# PIC32CX5112MTSH128S1 register map
Vendor: Microchip Technology; Series: PIC32CXMTSH; File version: 0
CPU: CM4 r0p1, selectable endian, MPU, FPU, 4 interrupt priority bits, 96 interrupts
Registers are 32-bit, read-write, reset 0x0 unless marked. A register's access mark holds for its fields unless they carry their own. Offsets are from the block's base; [hi:lo] are bit positions; {n}, {i} and the like mark numbered series.

## FLEXCOM0 (part 2 of 2) — Flexible Serial Communication
Base 0x40000000; register names take the prefix FLEXCOM_
Same registers: FLEXCOM1 0x40004000, FLEXCOM2 0x40008000, FLEXCOM3 0x4000C000, FLEXCOM4 0x40010000, FLEXCOM5 0x40014000, FLEXCOM6 0x40018000, FLEXCOM7 0x4001C000
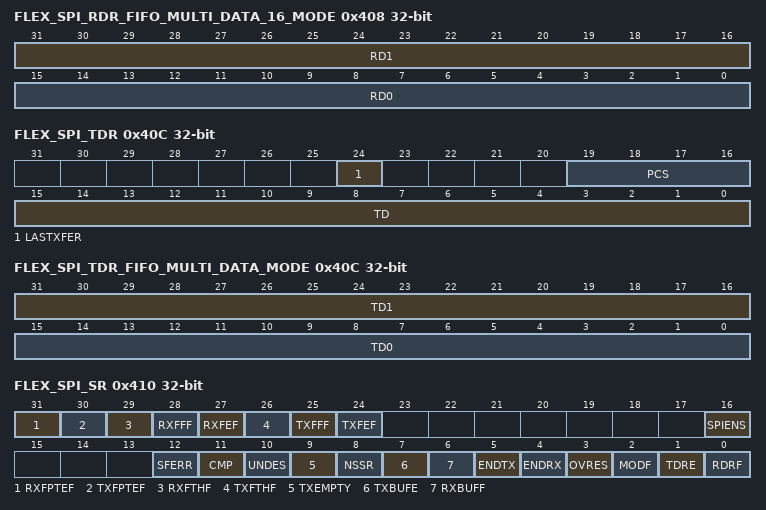
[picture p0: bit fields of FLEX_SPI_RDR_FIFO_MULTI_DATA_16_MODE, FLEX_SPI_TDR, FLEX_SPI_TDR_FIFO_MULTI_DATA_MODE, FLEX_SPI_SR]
0x408 FLEX_SPI_RDR_FIFO_MULTI_DATA_16_MODE ro (alternate view of FLEX_SPI_RDR) — SPI Receive Data Register
  [31:16] RD1 — Receive Data
  [15:0] RD0 — Receive Data
0x40C FLEX_SPI_TDR wo — SPI Transmit Data Register
  [24] LASTXFER — Last Transfer
  [19:16] PCS — Peripheral Chip Select
  [15:0] TD — Transmit Data
0x40C FLEX_SPI_TDR_FIFO_MULTI_DATA_MODE wo (alternate view of FLEX_SPI_TDR) — SPI Transmit Data Register
  [31:16] TD1 — Transmit Data
  [15:0] TD0 — Transmit Data
0x410 FLEX_SPI_SR ro — SPI Status Register
  [31] RXFPTEF — Receive FIFO Pointer Error Flag
  [30] TXFPTEF — Transmit FIFO Pointer Error Flag
  [29] RXFTHF — Receive FIFO Threshold Flag
  [28] RXFFF — Receive FIFO Full Flag
  [27] RXFEF — Receive FIFO Empty Flag
  [26] TXFTHF — Transmit FIFO Threshold Flag (cleared on read)
  [25] TXFFF — Transmit FIFO Full Flag (cleared on read)
  [24] TXFEF — Transmit FIFO Empty Flag (cleared on read)
  [16] SPIENS — SPI Enable Status
  [12] SFERR — Client Mode Frame Error (cleared on read)
  [11] CMP — Comparison Status (cleared on read)
  [10] UNDES — Underrun Error Status (Client mode only) (cleared on read)
  [9] TXEMPTY — Transmission Registers Empty (cleared by writing FLEX_SPI_TDR)
  [8] NSSR — NSS Rising (cleared on read)
  [7] TXBUFE — TX Buffer Empty (cleared by writing FLEX_SPI_TCR or FLEX_SPI_TNCR)
  [6] RXBUFF — RX Buffer Full (cleared by writing FLEX_SPI_RCR or FLEX_SPI_RNCR)
  [5] ENDTX — End of TX Buffer (cleared by writing FLEX_SPI_TCR or FLEX_SPI_TNCR)
  [4] ENDRX — End of RX Buffer (cleared by writing FLEX_SPI_RCR or FLEX_SPI_RNCR)
  [3] OVRES — Overrun Error Status (cleared on read)
  [2] MODF — Mode Fault Error (cleared on read)
  [1] TDRE — Transmit Data Register Empty (cleared by writing FLEX_SPI_TDR)
  [0] RDRF — Receive Data Register Full (cleared by reading FLEX_SPI_RDR)
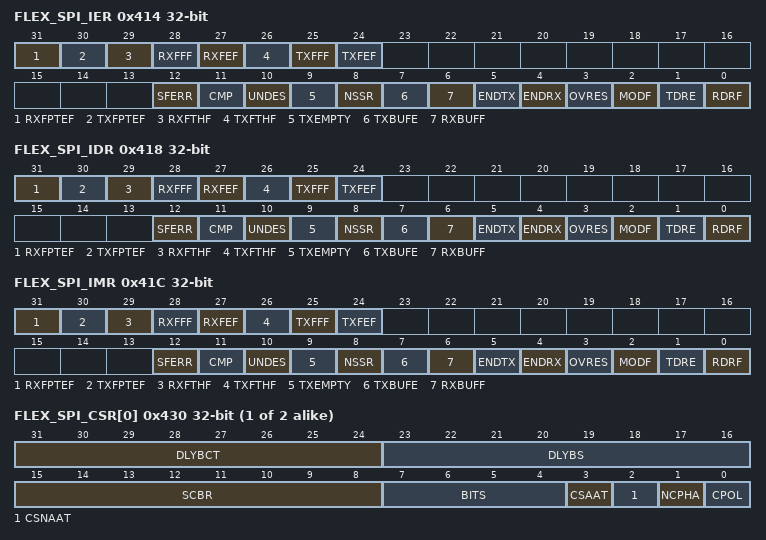
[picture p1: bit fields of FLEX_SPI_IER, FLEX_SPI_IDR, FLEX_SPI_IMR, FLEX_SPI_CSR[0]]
0x414 FLEX_SPI_IER wo — SPI Interrupt Enable Register
  [31] RXFPTEF — RXFPTEF Interrupt Enable
  [30] TXFPTEF — TXFPTEF Interrupt Enable
  [29] RXFTHF — RXFTHF Interrupt Enable
  [28] RXFFF — RXFFF Interrupt Enable
  [27] RXFEF — RXFEF Interrupt Enable
  [26] TXFTHF — TXFTHF Interrupt Enable
  [25] TXFFF — TXFFF Interrupt Enable
  [24] TXFEF — TXFEF Interrupt Enable
  [12] SFERR — Client Mode Frame Error Interrupt Enable
  [11] CMP — Comparison Interrupt Enable
  [10] UNDES — Underrun Error Interrupt Enable
  [9] TXEMPTY — Transmission Registers Empty Enable
  [8] NSSR — NSS Rising Interrupt Enable
  [7] TXBUFE — Transmit Buffer Empty Interrupt Enable
  [6] RXBUFF — Receive Buffer Full Interrupt Enable
  [5] ENDTX — End of Transmit Buffer Interrupt Enable
  [4] ENDRX — End of Receive Buffer Interrupt Enable
  [3] OVRES — Overrun Error Interrupt Enable
  [2] MODF — Mode Fault Error Interrupt Enable
  [1] TDRE — SPI Transmit Data Register Empty Interrupt Enable
  [0] RDRF — Receive Data Register Full Interrupt Enable
0x418 FLEX_SPI_IDR wo — SPI Interrupt Disable Register
  [31] RXFPTEF — RXFPTEF Interrupt Disable
  [30] TXFPTEF — TXFPTEF Interrupt Disable
  [29] RXFTHF — RXFTHF Interrupt Disable
  [28] RXFFF — RXFFF Interrupt Disable
  [27] RXFEF — RXFEF Interrupt Disable
  [26] TXFTHF — TXFTHF Interrupt Disable
  [25] TXFFF — TXFFF Interrupt Disable
  [24] TXFEF — TXFEF Interrupt Disable
  [12] SFERR — Client Mode Frame Error Interrupt Disable
  [11] CMP — Comparison Interrupt Disable
  [10] UNDES — Underrun Error Interrupt Disable
  [9] TXEMPTY — Transmission Registers Empty Disable
  [8] NSSR — NSS Rising Interrupt Disable
  [7] TXBUFE — Transmit Buffer Empty Interrupt Disable
  [6] RXBUFF — Receive Buffer Full Interrupt Disable
  [5] ENDTX — End of Transmit Buffer Interrupt Disable
  [4] ENDRX — End of Receive Buffer Interrupt Disable
  [3] OVRES — Overrun Error Interrupt Disable
  [2] MODF — Mode Fault Error Interrupt Disable
  [1] TDRE — SPI Transmit Data Register Empty Interrupt Disable
  [0] RDRF — Receive Data Register Full Interrupt Disable
0x41C FLEX_SPI_IMR ro — SPI Interrupt Mask Register
  [31] RXFPTEF — RXFPTEF Interrupt Mask
  [30] TXFPTEF — TXFPTEF Interrupt Mask
  [29] RXFTHF — RXFTHF Interrupt Mask
  [28] RXFFF — RXFFF Interrupt Mask
  [27] RXFEF — RXFEF Interrupt Mask
  [26] TXFTHF — TXFTHF Interrupt Mask
  [25] TXFFF — TXFFF Interrupt Mask
  [24] TXFEF — TXFEF Interrupt Mask
  [12] SFERR — Client Mode Frame Error Interrupt Mask
  [11] CMP — Comparison Interrupt Mask
  [10] UNDES — Underrun Error Interrupt Mask
  [9] TXEMPTY — Transmission Registers Empty Mask
  [8] NSSR — NSS Rising Interrupt Mask
  [7] TXBUFE — Transmit Buffer Empty Interrupt Mask
  [6] RXBUFF — Receive Buffer Full Interrupt Mask
  [5] ENDTX — End of Transmit Buffer Interrupt Mask
  [4] ENDRX — End of Receive Buffer Interrupt Mask
  [3] OVRES — Overrun Error Interrupt Mask
  [2] MODF — Mode Fault Error Interrupt Mask
  [1] TDRE — SPI Transmit Data Register Empty Interrupt Mask
  [0] RDRF — Receive Data Register Full Interrupt Mask
{0x430+4i} FLEX_SPI_CSR[{i}] (i=0..1) — SPI Chip Select Register
  [31:24] DLYBCT — Delay Between Consecutive Transfers
  [23:16] DLYBS — Delay Before SPCK
  [15:8] SCBR — Serial Clock Bit Rate
  [7:4] BITS — Bits Per Transfer
    {v}={v+8}_BIT ({v+8} bits for transfer) (v=0..8)
  [3] CSAAT — Chip Select Active After Transfer
  [2] CSNAAT — Chip Select Not Active After Transfer (Ignored if CSAAT = 1)
  [1] NCPHA — Clock Phase
  [0] CPOL — Clock Polarity
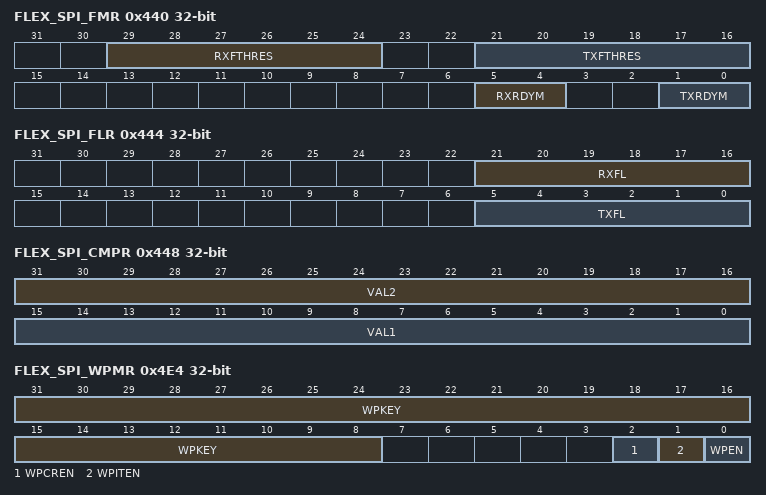
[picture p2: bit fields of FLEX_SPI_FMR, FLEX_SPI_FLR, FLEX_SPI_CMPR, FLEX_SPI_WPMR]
0x440 FLEX_SPI_FMR — SPI FIFO Mode Register
  [29:24] RXFTHRES — Receive FIFO Threshold
  [21:16] TXFTHRES — Transmit FIFO Threshold
  [5:4] RXRDYM — Receive Data Register Full Mode
    0=ONE_DATA (RDRF will be at level '1' when at least one unread data is in the receive FIFO. When DMA is enabled to transfer data and FLEX_SPI_CSR0.BITS=0 (8 bits transfered on SPI line), the chunk of 1 byte must be configured in the DMA. When FLEX_SPI_CSR0.BITS>0 (9 to 16 bits transfered on SPI line), the chunk of 1 halfword must be configured in the DMA. If the transfer is performed by software, the access type can be defined as byte or halfword depending on FLEX_SPI_CSR0.BITS.); 1=TWO_DATA (RDRF will be at level '1' when at least two unread data are in the receive FIFO. To minimize system bus load, when DMA is enabled to transfer data and FLEX_SPI_CSR0.BITS=0 (8 bits transfered on SPI line), the chunk of 1 halfword (1 halfword carries 2 bytes) must be configured in the DMA. When FLEX_SPI_CSR0.BITS>0 (9 to 16 bits transfered on SPI line), the chunk of 1 word (1 word carries 2 halfwords) must be configured in the DMA. If the transfer is performed by software, the access type can be defined as halfword (2 bytes per access, 1 access when FLEX_SPI_CSR0.BITS=0), or word (2 halfwords per access, 2 accesses when FLEX_SPI_CSR0.BITS>0).); 2=FOUR_DATA (RDRF will be at level '1' when at least four unread data are in the receive FIFO. To minimize system bus load, when DMA is enabled to transfer data and FLEX_SPI_CSR0.BITS=0 (8 bits transfered on SPI line), the chunk of 1 word (1 halfword carries 4 bytes) must be configured in the DMA. When FLEX_SPI_CSR0.BITS>0 (9 to 16 bits transfered on SPI line), the chunk of 2 words (1 word carries 4 bytes) must be configured in the DMA. If the transfer is performed by software, the access type can be defined as word (4 bytes per access, 1 access when FLEX_SPI_CSR0.BITS=0 or 2 halfwords per access, 2 accesses when FLEX_SPI_CSR0.BITS>0).)
  [1:0] TXRDYM — Transmit Data Register Empty Mode
    0=ONE_DATA (TDRE will be at level '1' when at least one data can be written in the transmit FIFO. When DMA is enabled to transfer data, the chunk of 1 data (byte or halfword) must be configured in the DMA depending on FLEX_SPI_CSR0.BITS. If the transfer is performed by software, the access type (byte, halfword) must be defined depending on FLEX_SPI_CSR0.BITS.); 1=TWO_DATA (TDRE will be at level '1' when at least two data can be written in the transmit FIFO. FIFO. To minimize system bus load, when DMA is enabled to transfer data, the chunk of 1 word (1 word carries 2 data) must be configured in the DMA. If the transfer is performed by software, the access type must be defined as word (2 data per access, 1 access).)
0x444 FLEX_SPI_FLR ro — SPI FIFO Level Register
  [21:16] RXFL — Receive FIFO Level
  [5:0] TXFL — Transmit FIFO Level
0x448 FLEX_SPI_CMPR — SPI Comparison Register
  [31:16] VAL2 — Second Comparison Value for Received Character
  [15:0] VAL1 — First Comparison Value for Received Character
0x4E4 FLEX_SPI_WPMR — SPI Write Protection Mode Register
  [31:8] WPKEY — Write Protection Key
    0x535049=PASSWD (Writing any other value in this field aborts the write operation of bits WPEN, WPITEN and WPCREN. Always reads as 0)
  [2] WPCREN — Write Protection Control Enable
  [1] WPITEN — Write Protection Interrupt Enable
  [0] WPEN — Write Protection Enable
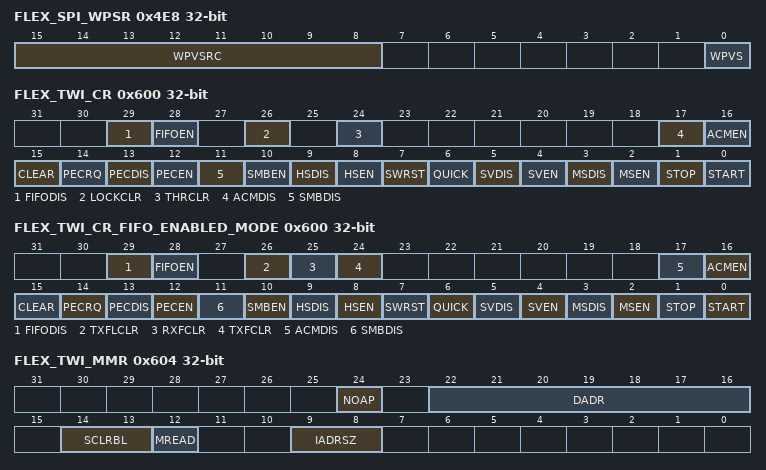
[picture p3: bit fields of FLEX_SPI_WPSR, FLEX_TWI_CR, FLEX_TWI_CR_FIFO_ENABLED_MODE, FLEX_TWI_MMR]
0x4E8 FLEX_SPI_WPSR ro — SPI Write Protection Status Register
  [15:8] WPVSRC — Write Protection Violation Source
  [0] WPVS — Write Protection Violation Status
0x600 FLEX_TWI_CR wo — TWI Control Register
  [29] FIFODIS — FIFO Disable
  [28] FIFOEN — FIFO Enable
  [26] LOCKCLR — Lock Clear
  [24] THRCLR — Transmit Holding Register Clear
  [17] ACMDIS — Alternative Command Mode Disable
  [16] ACMEN — Alternative Command Mode Enable
  [15] CLEAR — Bus CLEAR Command
  [14] PECRQ — PEC Request
  [13] PECDIS — Packet Error Checking Disable
  [12] PECEN — Packet Error Checking Enable
  [11] SMBDIS — SMBus Mode Disabled
  [10] SMBEN — SMBus Mode Enabled
  [9] HSDIS — TWI High-Speed Mode Disabled
  [8] HSEN — TWI High-Speed Mode Enabled
  [7] SWRST — Software Reset
  [6] QUICK — SMBus Quick Command
  [5] SVDIS — TWI Client Mode Disabled
  [4] SVEN — TWI Client Mode Enabled
  [3] MSDIS — TWI Host Mode Disabled
  [2] MSEN — TWI Host Mode Enabled
  [1] STOP — Send a STOP Condition
  [0] START — Send a START Condition
0x600 FLEX_TWI_CR_FIFO_ENABLED_MODE wo (alternate view of FLEX_TWI_CR) — TWI Control Register
  [29] FIFODIS — FIFO Disable
  [28] FIFOEN — FIFO Enable
  [26] TXFLCLR — Transmit FIFO Lock CLEAR
  [25] RXFCLR — Receive FIFO Clear
  [24] TXFCLR — Transmit FIFO Clear
  [17] ACMDIS — Alternative Command Mode Disable
  [16] ACMEN — Alternative Command Mode Enable
  [15] CLEAR — Bus CLEAR Command
  [14] PECRQ — PEC Request
  [13] PECDIS — Packet Error Checking Disable
  [12] PECEN — Packet Error Checking Enable
  [11] SMBDIS — SMBus Mode Disabled
  [10] SMBEN — SMBus Mode Enabled
  [9] HSDIS — TWI High-Speed Mode Disabled
  [8] HSEN — TWI High-Speed Mode Enabled
  [7] SWRST — Software Reset
  [6] QUICK — SMBus Quick Command
  [5] SVDIS — TWI Client Mode Disabled
  [4] SVEN — TWI Client Mode Enabled
  [3] MSDIS — TWI Host Mode Disabled
  [2] MSEN — TWI Host Mode Enabled
  [1] STOP — Send a STOP Condition
  [0] START — Send a START Condition
0x604 FLEX_TWI_MMR — TWI Host Mode Register
  [24] NOAP — No Auto-Stop On NACK Error
  [22:16] DADR — Device Address
  [14:13] SCLRBL — SCL Rise Boost Level
  [12] MREAD — Host Read Direction
  [9:8] IADRSZ — Internal Device Address Size
    0=NONE (No internal device address); 1=1_BYTE (One-byte internal device address); 2=2_BYTE (Two-byte internal device address); 3=3_BYTE (Three-byte internal device address)
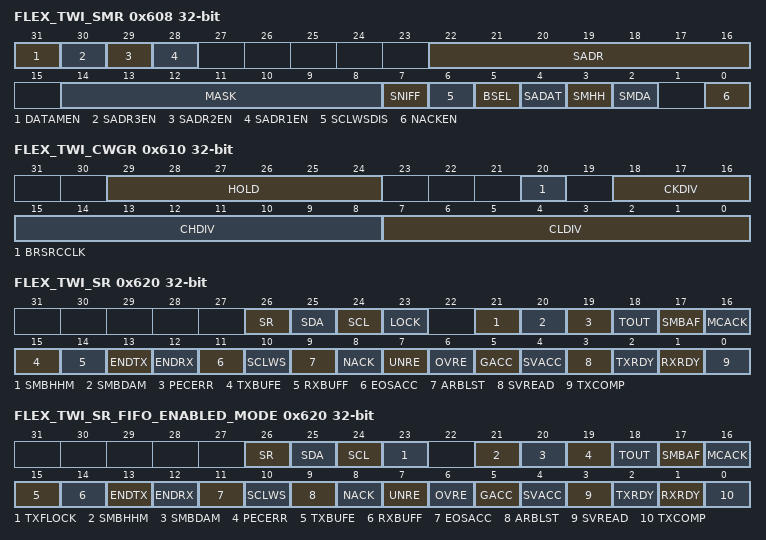
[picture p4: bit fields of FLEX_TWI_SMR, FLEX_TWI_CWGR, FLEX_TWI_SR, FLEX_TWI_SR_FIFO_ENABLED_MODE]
0x608 FLEX_TWI_SMR — TWI Client Mode Register
  [31] DATAMEN — Data Matching Enable
  [30] SADR3EN — Client Address 3 Enable
  [29] SADR2EN — Client Address 2 Enable
  [28] SADR1EN — Client Address 1 Enable
  [22:16] SADR — Client Address
  [14:8] MASK — Client Address Mask
  [7] SNIFF — Client Sniffer Mode
  [6] SCLWSDIS — Clock Wait State Disable
  [5] BSEL — TWI Bus Selection
  [4] SADAT — Client Address Treated as Data
  [3] SMHH — SMBus Host Header
  [2] SMDA — SMBus Default Address
  [0] NACKEN — Client Receiver Data Phase NACK Enable
0x60C FLEX_TWI_IADR — TWI Internal Address Register
  [23:0] IADR — Internal Address
0x610 FLEX_TWI_CWGR — TWI Clock Waveform Generator Register
  [29:24] HOLD — TWD Hold Time Versus TWCK Falling
  [20] BRSRCCLK — Bit Rate Source Clock
    0=PERIPH_CLK (The peripheral clock is the source clock for the bit rate generation.); 1=GCLK (GCLK is the source clock for the bit rate generation, thus the bit rate can be independent of the core/peripheral clock.)
  [18:16] CKDIV — Clock Divider
  [15:8] CHDIV — Clock High Divider
  [7:0] CLDIV — Clock Low Divider
0x620 FLEX_TWI_SR ro — TWI Status Register
  [26] SR — Start Repeated
  [25] SDA — SDA Line Value
  [24] SCL — SCL Line Value
  [23] LOCK — TWI Lock Due to Frame Errors
  [21] SMBHHM — SMBus Host Header Address Match (cleared on read)
  [20] SMBDAM — SMBus Default Address Match (cleared on read)
  [19] PECERR — PEC Error (cleared on read)
  [18] TOUT — Timeout Error (cleared on read)
  [17] SMBAF — SMBus Alert Flag
  [16] MCACK — Host Code Acknowledge (cleared on read)
  [15] TXBUFE — TX Buffer Empty (cleared by writing FLEX_TWI_TCR or FLEX_TWI_TNCR)
  [14] RXBUFF — RX Buffer Full (cleared by writing FLEX_TWI_RCR or FLEX_TWI_RNCR)
  [13] ENDTX — End of TX Buffer (cleared by writing FLEX_TWI_TCR or FLEX_TWI_TNCR)
  [12] ENDRX — End of RX Buffer (cleared by writing FLEX_TWI_RCR or FLEX_TWI_RNCR)
  [11] EOSACC — End Of Client Access (cleared on read)
  [10] SCLWS — Clock Wait State
  [9] ARBLST — Arbitration Lost (cleared on read)
  [8] NACK — Not Acknowledged (cleared on read)
  [7] UNRE — Underrun Error (cleared on read)
  [6] OVRE — Overrun Error (cleared on read)
  [5] GACC — General Call Access (cleared on read)
  [4] SVACC — Client Access
  [3] SVREAD — Client Read
  [2] TXRDY — Transmit Holding Register Ready (cleared by writing FLEX_TWI_THR)
  [1] RXRDY — Receive Holding Register Ready (cleared when reading FLEX_TWI_RHR)
  [0] TXCOMP — Transmission Completed (cleared by writing FLEX_TWI_THR)
0x620 FLEX_TWI_SR_FIFO_ENABLED_MODE ro (alternate view of FLEX_TWI_SR) — TWI Status Register
  [26] SR — Start Repeated
  [25] SDA — SDA Line Value
  [24] SCL — SCL Line Value
  [23] TXFLOCK — Transmit FIFO Lock
  [21] SMBHHM — SMBus Host Header Address Match (cleared on read)
  [20] SMBDAM — SMBus Default Address Match (cleared on read)
  [19] PECERR — PEC Error (cleared on read)
  [18] TOUT — Timeout Error (cleared on read)
  [17] SMBAF — SMBus Alert Flag
  [16] MCACK — Host Code Acknowledge (cleared on read)
  [15] TXBUFE — TX Buffer Empty (cleared by writing FLEX_TWI_TCR or FLEX_TWI_TNCR)
  [14] RXBUFF — RX Buffer Full (cleared by writing FLEX_TWI_RCR or FLEX_TWI_RNCR)
  [13] ENDTX — End of TX Buffer (cleared by writing FLEX_TWI_TCR or FLEX_TWI_TNCR)
  [12] ENDRX — End of RX Buffer (cleared by writing FLEX_TWI_RCR or FLEX_TWI_RNCR)
  [11] EOSACC — End Of Client Access (cleared on read)
  [10] SCLWS — Clock Wait State
  [9] ARBLST — Arbitration Lost (cleared on read)
  [8] NACK — Not Acknowledged (cleared on read)
  [7] UNRE — Underrun Error (cleared on read)
  [6] OVRE — Overrun Error (cleared on read)
  [5] GACC — General Call Access (cleared on read)
  [4] SVACC — Client Access
  [3] SVREAD — Client Read
  [2] TXRDY — Transmit Holding Register Ready (cleared by writing FLEX_TWI_THR)
  [1] RXRDY — Receive Holding Register Ready (cleared when reading FLEX_TWI_RHR)
  [0] TXCOMP — Transmission Completed (cleared by writing FLEX_TWI_THR)
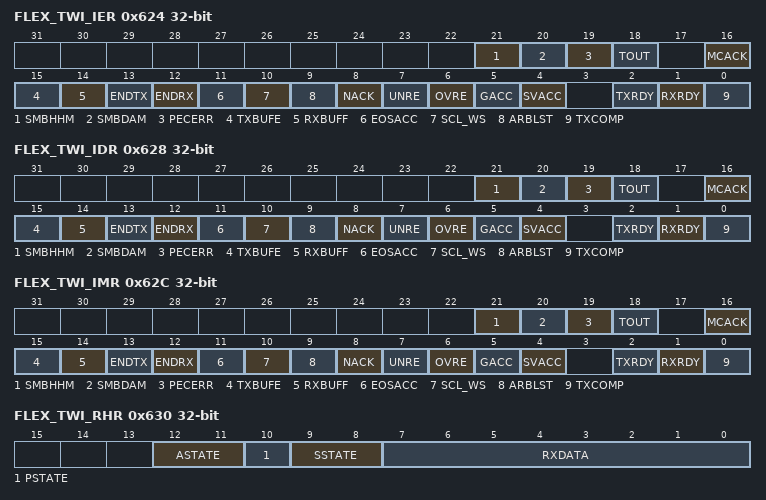
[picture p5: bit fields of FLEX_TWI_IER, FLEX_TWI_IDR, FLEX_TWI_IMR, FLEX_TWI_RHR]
0x624 FLEX_TWI_IER wo — TWI Interrupt Enable Register
  [21] SMBHHM — SMBus Host Header Address Match Interrupt Enable
  [20] SMBDAM — SMBus Default Address Match Interrupt Enable
  [19] PECERR — PEC Error Interrupt Enable
  [18] TOUT — Timeout Error Interrupt Enable
  [16] MCACK — Host Code Acknowledge Interrupt Enable
  [15] TXBUFE — Transmit Buffer Empty Interrupt Enable
  [14] RXBUFF — Receive Buffer Full Interrupt Enable
  [13] ENDTX — End of Transmit Buffer Interrupt Enable
  [12] ENDRX — End of Receive Buffer Interrupt Enable
  [11] EOSACC — End Of Client Access Interrupt Enable
  [10] SCL_WS — Clock Wait State Interrupt Enable
  [9] ARBLST — Arbitration Lost Interrupt Enable
  [8] NACK — Not Acknowledge Interrupt Enable
  [7] UNRE — Underrun Error Interrupt Enable
  [6] OVRE — Overrun Error Interrupt Enable
  [5] GACC — General Call Access Interrupt Enable
  [4] SVACC — Client Access Interrupt Enable
  [2] TXRDY — Transmit Holding Register Ready Interrupt Enable
  [1] RXRDY — Receive Holding Register Ready Interrupt Enable
  [0] TXCOMP — Transmission Completed Interrupt Enable
0x628 FLEX_TWI_IDR wo — TWI Interrupt Disable Register
  [21] SMBHHM — SMBus Host Header Address Match Interrupt Disable
  [20] SMBDAM — SMBus Default Address Match Interrupt Disable
  [19] PECERR — PEC Error Interrupt Disable
  [18] TOUT — Timeout Error Interrupt Disable
  [16] MCACK — Host Code Acknowledge Interrupt Disable
  [15] TXBUFE — Transmit Buffer Empty Interrupt Disable
  [14] RXBUFF — Receive Buffer Full Interrupt Disable
  [13] ENDTX — End of Transmit Buffer Interrupt Disable
  [12] ENDRX — End of Receive Buffer Interrupt Disable
  [11] EOSACC — End Of Client Access Interrupt Disable
  [10] SCL_WS — Clock Wait State Interrupt Disable
  [9] ARBLST — Arbitration Lost Interrupt Disable
  [8] NACK — Not Acknowledge Interrupt Disable
  [7] UNRE — Underrun Error Interrupt Disable
  [6] OVRE — Overrun Error Interrupt Disable
  [5] GACC — General Call Access Interrupt Disable
  [4] SVACC — Client Access Interrupt Disable
  [2] TXRDY — Transmit Holding Register Ready Interrupt Disable
  [1] RXRDY — Receive Holding Register Ready Interrupt Disable
  [0] TXCOMP — Transmission Completed Interrupt Disable
0x62C FLEX_TWI_IMR ro — TWI Interrupt Mask Register
  [21] SMBHHM — SMBus Host Header Address Match Interrupt Mask
  [20] SMBDAM — SMBus Default Address Match Interrupt Mask
  [19] PECERR — PEC Error Interrupt Mask
  [18] TOUT — Timeout Error Interrupt Mask
  [16] MCACK — Host Code Acknowledge Interrupt Mask
  [15] TXBUFE — Transmit Buffer Empty Interrupt Mask
  [14] RXBUFF — Receive Buffer Full Interrupt Mask
  [13] ENDTX — End of Transmit Buffer Interrupt Mask
  [12] ENDRX — End of Receive Buffer Interrupt Mask
  [11] EOSACC — End Of Client Access Interrupt Mask
  [10] SCL_WS — Clock Wait State Interrupt Mask
  [9] ARBLST — Arbitration Lost Interrupt Mask
  [8] NACK — Not Acknowledge Interrupt Mask
  [7] UNRE — Underrun Error Interrupt Mask
  [6] OVRE — Overrun Error Interrupt Mask
  [5] GACC — General Call Access Interrupt Mask
  [4] SVACC — Client Access Interrupt Mask
  [2] TXRDY — Transmit Holding Register Ready Interrupt Mask
  [1] RXRDY — Receive Holding Register Ready Interrupt Mask
  [0] TXCOMP — Transmission Completed Interrupt Mask
0x630 FLEX_TWI_RHR ro — TWI Receive Holding Register
  [12:11] ASTATE — Acknowledge State (Client Sniffer Mode only)
    0=NONE (No Acknowledge or Nacknowledge detected after previously logged data); 1=ACK (Acknowledge (A) detected after previously logged data); 2=NACK (Nacknowledge (NA) detected after previously logged data); 3=UNDEF (Not defined)
  [10] PSTATE — Stop State (Client Sniffer Mode only)
  [9:8] SSTATE — Start State (Client Sniffer Mode only)
    0=NOSTART (No START detected with the logged data); 1=START (START (S) detected with the logged data); 2=RSTART (Repeated START (Sr) detected with the logged data); 3=UNDEF (Not defined)
  [7:0] RXDATA — Host or Client Receive Holding Data
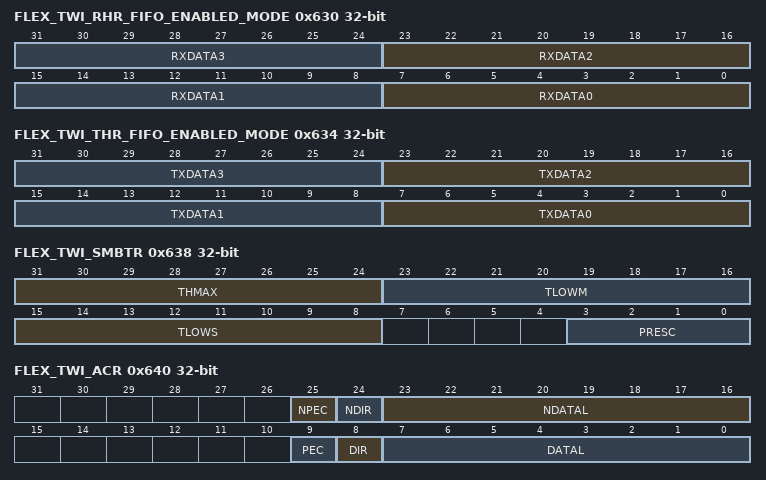
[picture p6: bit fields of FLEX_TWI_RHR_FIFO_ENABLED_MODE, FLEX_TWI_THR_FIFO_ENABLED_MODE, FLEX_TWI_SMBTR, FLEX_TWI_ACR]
0x630 FLEX_TWI_RHR_FIFO_ENABLED_MODE ro (alternate view of FLEX_TWI_RHR) — TWI Receive Holding Register
  [8n+7:8n] RXDATA{n} (n=0..3) — Host or Client Receive Holding Data {n}
0x634 FLEX_TWI_THR wo — TWI Transmit Holding Register
  [7:0] TXDATA — Host or Client Transmit Holding Data
0x634 FLEX_TWI_THR_FIFO_ENABLED_MODE wo (alternate view of FLEX_TWI_THR) — TWI Transmit Holding Register
  [8n+7:8n] TXDATA{n} (n=0..3) — Host or Client Transmit Holding Data {n}
0x638 FLEX_TWI_SMBTR — TWI SMBus Timing Register
  [31:24] THMAX — Clock High Maximum Cycles
  [23:16] TLOWM — Host Clock Stretch Maximum Cycles
  [15:8] TLOWS — Client Clock Stretch Maximum Cycles
  [3:0] PRESC — SMBus Clock Prescaler
0x63C FLEX_TWI_HSR — TWI High Speed Register
  [7:0] MCODE — TWI High Speed Host Code
0x640 FLEX_TWI_ACR — TWI Alternative Command Register
  [25] NPEC — Next PEC Request (SMBus Mode only)
  [24] NDIR — Next Transfer Direction
  [23:16] NDATAL — Next Data Length
  [9] PEC — PEC Request (SMBus Mode only)
  [8] DIR — Transfer Direction
  [7:0] DATAL — Data Length
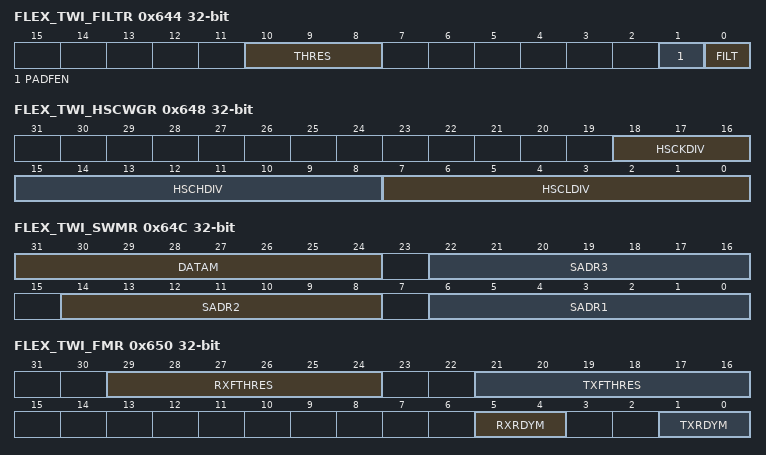
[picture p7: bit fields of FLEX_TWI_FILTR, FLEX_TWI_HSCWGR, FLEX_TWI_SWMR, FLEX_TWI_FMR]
0x644 FLEX_TWI_FILTR — TWI Filter Register
  [10:8] THRES — Digital Filter Threshold
  [1] PADFEN — PAD Filter Enable
  [0] FILT — RX Digital Filter
0x648 FLEX_TWI_HSCWGR — TWI High Speed Clock Waveform Generator Register
  [18:16] HSCKDIV — High Speed Clock Divider
  [15:8] HSCHDIV — High Speed Clock High Divider
  [7:0] HSCLDIV — High Speed Clock Low Divider
0x64C FLEX_TWI_SWMR — TWI Matching Register
  [31:24] DATAM — Data Match
  [22:16] SADR3 — Client Address 3
  [14:8] SADR2 — Client Address 2
  [6:0] SADR1 — Client Address 1
0x650 FLEX_TWI_FMR — TWI FIFO Mode Register
  [29:24] RXFTHRES — Receive FIFO Threshold
  [21:16] TXFTHRES — Transmit FIFO Threshold
  [5:4] RXRDYM — Receiver Ready Mode
    0=ONE_DATA (RXRDY will be at level '1' when at least one unread data is in the receive FIFO. When DMA is enabled to transfer data the chunk of 1 byte must be configured in the DMA. If the transfer is performed by software, the access type (byte, halfword) must be defined accordingly.); 1=TWO_DATA (RXRDY will be at level '1' when at least two unread data are in the receive FIFO. To minimize system bus load, when DMA is enabled to transfer data, the chunk of 1 halfword (1 halfword carries 2 bytes) must be configured in the DMA. If the transfer is performed by software, the access type can be defined as byte (1 byte per access, 2 accesses) or halfword (2 bytes per access, 1 single access).); 2=FOUR_DATA (RXRDY will be at level '1' when at least four unread data are in the receive FIFO. To minimize system bus load, when DMA is enabled to transfer data, the chunk of 1 word (1 word carries 4 bytes) must be configured in the DMA. If the transfer is performed by software, the access type can be defined as byte (1 byte per access, 4 accesses), halfword (2 bytes per access, 2 accesses) or word (4 bytes per access, 1 single access).)
  [1:0] TXRDYM — Transmitter Ready Mode
    0=ONE_DATA (TXRDY will be at level '1' when at least one data can be written in the transmit FIFO. When DMA is enabled to transfer data, the chunk of 1 byte must be configured in the DMA. If the transfer is performed by software, the access type must be defined as byte.); 1=TWO_DATA (TXRDY will be at level '1' when at least two data can be written in the transmit FIFO. To minimize system bus load, when DMA is enabled to transfer data, the chunk of 1 halfword (1 halfword carries 2 bytes) must be configured in the DMA. If the transfer is performed by software, the access type can be defined as byte (1 byte per access, 2 accesses) or halfword (2 bytes per access, 1 single access).); 2=FOUR_DATA (TXRDY will be at level '1' when at least four data can be written in the transmit FIFO. To minimize system bus load, when DMA is enabled to transfer data, the chunk of 1 word (1 word carries 4 bytes) must be configured in the DMA. If the transfer is performed by software, the access type can be defined as byte (1 byte per access, 4 accesses), halfword (2 bytes per access, 2 accesses) or word (4 bytes per access, 1 single access).)
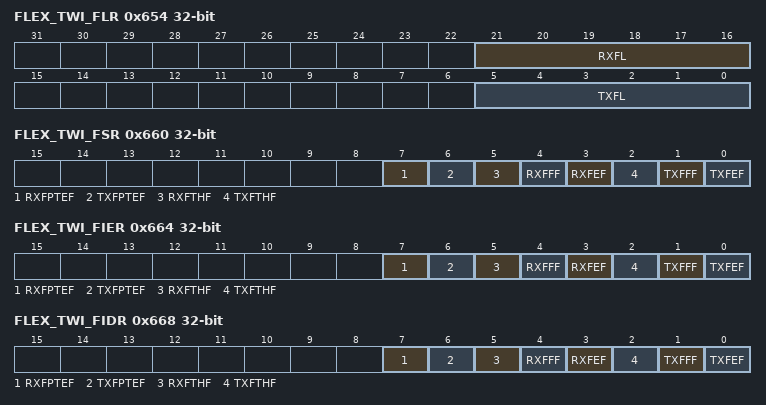
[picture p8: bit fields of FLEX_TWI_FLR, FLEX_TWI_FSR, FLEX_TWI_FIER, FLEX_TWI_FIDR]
0x654 FLEX_TWI_FLR ro — TWI FIFO Level Register
  [21:16] RXFL — Receive FIFO Level
  [5:0] TXFL — Transmit FIFO Level
0x660 FLEX_TWI_FSR ro — TWI FIFO Status Register
  [7] RXFPTEF — Receive FIFO Pointer Error Flag
  [6] TXFPTEF — Transmit FIFO Pointer Error Flag
  [5] RXFTHF — Receive FIFO Threshold Flag
  [4] RXFFF — Receive FIFO Full Flag
  [3] RXFEF — Receive FIFO Empty Flag
  [2] TXFTHF — Transmit FIFO Threshold Flag (cleared on read)
  [1] TXFFF — Transmit FIFO Full Flag (cleared on read)
  [0] TXFEF — Transmit FIFO Empty Flag (cleared on read)
0x664 FLEX_TWI_FIER wo — TWI FIFO Interrupt Enable Register
  [7] RXFPTEF — RXFPTEF Interrupt Enable
  [6] TXFPTEF — TXFPTEF Interrupt Enable
  [5] RXFTHF — RXFTHF Interrupt Enable
  [4] RXFFF — RXFFF Interrupt Enable
  [3] RXFEF — RXFEF Interrupt Enable
  [2] TXFTHF — TXFTHF Interrupt Enable
  [1] TXFFF — TXFFF Interrupt Enable
  [0] TXFEF — TXFEF Interrupt Enable
0x668 FLEX_TWI_FIDR wo — TWI FIFO Interrupt Disable Register
  [7] RXFPTEF — RXFPTEF Interrupt Disable
  [6] TXFPTEF — TXFPTEF Interrupt Disable
  [5] RXFTHF — RXFTHF Interrupt Disable
  [4] RXFFF — RXFFF Interrupt Disable
  [3] RXFEF — RXFEF Interrupt Disable
  [2] TXFTHF — TXFTHF Interrupt Disable
  [1] TXFFF — TXFFF Interrupt Disable
  [0] TXFEF — TXFEF Interrupt Disable
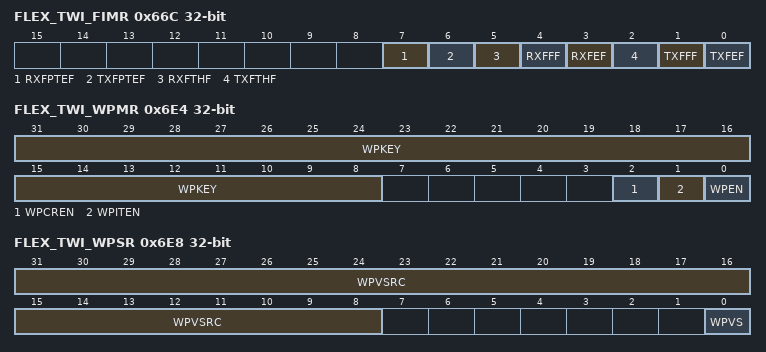
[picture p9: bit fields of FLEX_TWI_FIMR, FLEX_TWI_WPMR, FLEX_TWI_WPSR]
0x66C FLEX_TWI_FIMR ro — TWI FIFO Interrupt Mask Register
  [7] RXFPTEF — RXFPTEF Interrupt Mask
  [6] TXFPTEF — TXFPTEF Interrupt Mask
  [5] RXFTHF — RXFTHF Interrupt Mask
  [4] RXFFF — RXFFF Interrupt Mask
  [3] RXFEF — RXFEF Interrupt Mask
  [2] TXFTHF — TXFTHF Interrupt Mask
  [1] TXFFF — TXFFF Interrupt Mask
  [0] TXFEF — TXFEF Interrupt Mask
0x6E4 FLEX_TWI_WPMR — TWI Write Protection Mode Register
  [31:8] WPKEY — Write Protection Key
    0x545749=PASSWD (Writing any other value in this field aborts the write operation of bits WPEN, WPITEN and WPCREN. Always reads as 0)
  [2] WPCREN — Write Protection Control Enable
  [1] WPITEN — Write Protection Interrupt Enable
  [0] WPEN — Write Protection Enable
0x6E8 FLEX_TWI_WPSR ro — TWI Write Protection Status Register
  [31:8] WPVSRC — Write Protection Violation Source
  [0] WPVS — Write Protect Violation Status (cleared on read)

## Notices in the file
Copyright (c) 2023 Microchip Technology Inc.
SPDX-License-Identifier: Apache-2.0
Licensed under the Apache License, Version 2.0 (the "License");
you may not use this file except in compliance with the License.
You may obtain a copy of the License at
http://www.apache.org/licenses/LICENSE-2.0
Unless required by applicable law or agreed to in writing, software
distributed under the License is distributed on an "AS IS" BASIS,
WITHOUT WARRANTIES OR CONDITIONS OF ANY KIND, either express or implied.
See the License for the specific language governing permissions and
limitations under the License.
